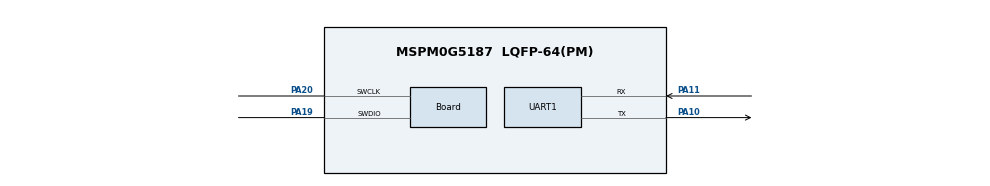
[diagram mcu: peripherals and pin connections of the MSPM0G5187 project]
//@cliArgs --device "MSPM0G518X" --part "Default" --package "LQFP-64(PM)" 
//@v2CliArgs --device "MSPM0G5187" --package "LQFP-64(PM)"  
// @cliArgs --board /ti/boards/LP_MSPM0G5187 --rtos nortos

/**
 * Import the modules used in this configuration.
 */
const Board         = scripting.addModule("/ti/driverlib/Board");
const CRCP          = scripting.addModule("/ti/driverlib/CRCP");
const SYSCTL        = scripting.addModule("/ti/driverlib/SYSCTL");
const UART          = scripting.addModule("/ti/driverlib/UART", {}, false);
const UART1         = UART.addInstance();
const ProjectConfig = scripting.addModule("/ti/project_config/ProjectConfig");

/**
 * Write custom configuration values to the imported modules.
 */
Board.configureUnused             = true;
Board.peripheral.$assign          = "DEBUGSS";
Board.peripheral.swclkPin.$assign = "PA20";
Board.peripheral.swdioPin.$assign = "PA19";

CRCP.polynomial = "16_POLYNOMIAL_CCIT_ZERO";
CRCP.seed       = 0xFFFF;

SYSCTL.peripheral.$assign = "SYSCTL";

UART1.$name                        = "UART_0";
UART1.enableFIFO                   = true;
UART1.rxFifoThreshold              = "DL_UART_RX_FIFO_LEVEL_ONE_ENTRY";
UART1.txFifoThreshold              = "DL_UART_TX_FIFO_LEVEL_3_4_EMPTY";
UART1.targetBaudRate               = 115200;
UART1.enableDMARX                  = false;
UART1.enableDMATX                  = false;
UART1.enabledInterrupts            = ["RX","TX"];
UART1.peripheral.$assign           = "UC0";
UART1.peripheral.rxPin.$assign     = "PA11";
UART1.peripheral.txPin.$assign     = "PA10";
UART1.txPinConfig.internalResistor = "PULL_UP";

ProjectConfig.migrationCondition = true;
